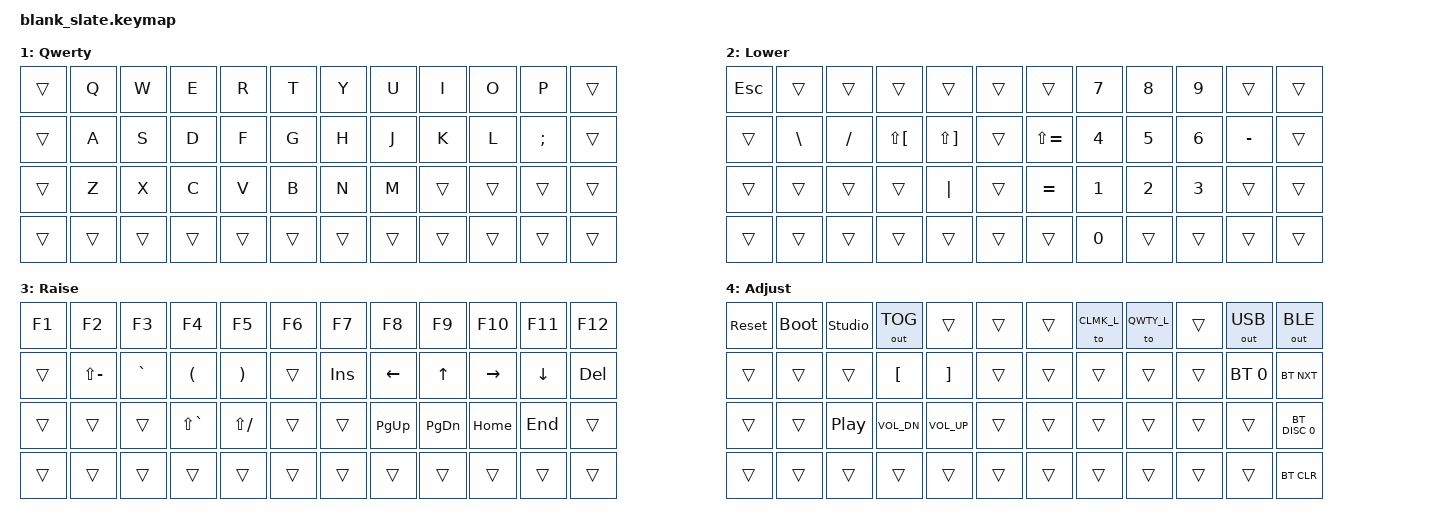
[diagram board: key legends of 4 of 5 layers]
/*
 * Copyright (c) 2022 Pete Johanson
 *
 * SPDX-License-Identifier: MIT
 */

#include <behaviors.dtsi>
#include <dt-bindings/zmk/keys.h>
#include <dt-bindings/zmk/bt.h>
#include <dt-bindings/zmk/outputs.h>

#define CLMK_L 0
#define QWTY_L 1
#define LOWR_L 2
#define UPPR_L 3
#define AJST_L 4

// Using layer taps on thumbs, having quick tap as well helps w/ repeating space/backspace
&lt { quick_tap_ms = <200>; };

#define BT(n) BT_SEL n

/ {
    chosen {
       zmk,physical-layout = &layout_ortho_4x12_1x2u;
    };

		/*   macros { */
		/*     ZMK_MACRO(thumbs_up, */
		/* wait-ms = <1>; */
		/* tap-ms = <5>; */
		/*               bindings = <&kp PLUS &kp COLON &kp PLUS &kp N1 &kp COLON &kp RET>; */
		/* ) */
		/*   }; */
		/**/
		/*   tap_dances { */
		/*   	shifty: shift_caps_word { */
		/* 	compatible = "zmk,behavior-tap-dance"; */
		/* 	display-name = "TD_SHIFTY"; */
		/* 	#binding-cells = <0>; */
		/* 	tapping-term-ms = <150>; */
		/* 	bindings = <&kp LSHFT>, <&caps_word>; */
		/* }; */
		/*   }; */
			
	behaviors {
        morph_dot: morph_dot {
            compatible = "zmk,behavior-mod-morph";
            #binding-cells = <0>;
            bindings = <&kp DOT>, <&kp LESS_THAN>;
            mods = <(MOD_LSFT|MOD_RSFT)>;
		};
        morph_comma: morph_comma {
            compatible = "zmk,behavior-mod-morph";
            #binding-cells = <0>;
            bindings = <&kp COMMA>, <&kp GREATER_THAN>;
            mods = <(MOD_LSFT|MOD_RSFT)>;
		};
    };

    cond_layers {
        compatible = "zmk,conditional-layers";
		tri {
			if-layers = <LOWR_L UPPR_L>;
			then-layer = <AJST_L>;
		};
    };

    keymap {
        compatible = "zmk,keymap";

        colemak_layer {
            display-name = "Colemak";
            bindings = <
                &kp TAB		&kp Q      &kp W      &kp F       &kp P       &kp G       &kp J       &kp L       &kp U        &kp Y        &kp SEMI     &kp ESC
                &kp LCTRL	&kp A      &kp R      &kp S       &kp T       &kp D       &kp H       &kp N       &kp E        &kp I        &kp O        &kp BSPC
                &kp LSHFT	&kp Z      &kp X      &kp C       &kp V       &kp B       &kp K       &kp M       &morph_dot   &morph_comma	&kp SQT      &kp RET
                &kp LCTRL	&kp PG_UP  &kp LALT   &kp LGUI    &mo LOWR_L        &kp SPACE         &mo UPPR_L  &kp RSHFT    &kp RCTRL    &kp RALT     &kp CAPS
            >;
        };

        qwerty_layer {
            display-name = "Qwerty";
            bindings = <
                &trans     &kp Q      &kp W      &kp E       &kp R       &kp T       &kp Y       &kp U       &kp I        &kp O        &kp P        &trans
                &trans     &kp A      &kp S      &kp D       &kp F       &kp G       &kp H       &kp J       &kp K        &kp L        &kp SEMI     &trans
                &trans     &kp Z      &kp X      &kp C       &kp V       &kp B       &kp N       &kp M       &trans       &trans       &trans       &trans
                &trans     &trans     &trans     &trans      &trans      &trans      &trans      &trans      &trans       &trans       &trans       &trans
            >;
        };

        lower_layer {
            display-name = "Lower";
            bindings = <
                &kp ESC	   &trans         &trans         &trans       &trans       &trans       &trans           &kp N7       &kp N8       &kp N9       &trans        &trans
                &trans     &kp BSLH		  &kp FSLH       &kp LS(LBKT) &kp LS(RBKT) &trans       &kp LS(EQUAL)    &kp N4       &kp N5       &kp N6       &kp MINUS     &trans
                &trans     &trans         &trans		 &trans		  &kp PIPE	   &trans       &kp EQUAL        &kp N1       &kp N2       &kp N3       &trans        &trans
                &trans     &trans         &trans         &trans       &trans       &trans       &trans           &kp N0       &trans       &trans       &trans        &trans
            >;
        };

        raise_layer {
            display-name = "Raise";
            bindings = <
                &kp F1     &kp F2			&kp F3     &kp F4           &kp F5           &kp F6       &kp F7       &kp F8       &kp F9       &kp F10      &kp F11      &kp F12
                &trans     &kp LS(MINUS)	&kp GRAVE  &kp LPAR         &kp RPAR         &trans       &kp INS      &kp LEFT     &kp UP       &kp RIGHT    &kp DOWN     &kp DEL
                &trans     &trans			&trans     &kp LS(GRAVE)    &kp LS(FSLH)     &trans       &trans       &kp PG_UP    &kp PG_DN    &kp HOME     &kp END      &trans
                &trans     &trans			&trans     &trans           &trans           &trans       &trans       &trans       &trans       &trans       &trans       &trans
            >;
        };
	
        adjust_layer {
            display-name = "Adjust";
            bindings = <
                &sys_reset	&bootloader		&studio_unlock	&out OUT_TOG     &trans           &trans           &trans           &to CLMK_L       &to QWTY_L       &trans           &out OUT_USB		&out OUT_BLE
                &trans		&trans			&trans			&kp LBKT         &kp RBKT		  &trans           &trans           &trans           &trans	          &trans           &bt BT_SEL 0		&bt BT_NXT
                &trans		&trans          &kp C_PP		&kp C_VOL_DN	 &kp C_VOL_UP     &trans           &trans           &trans           &trans           &trans           &trans           &bt BT_DISC 0
                &trans		&trans			&trans			&trans           &trans           &trans           &trans           &trans           &trans           &trans           &trans           &bt BT_CLR
            >;
        };
    };


};

